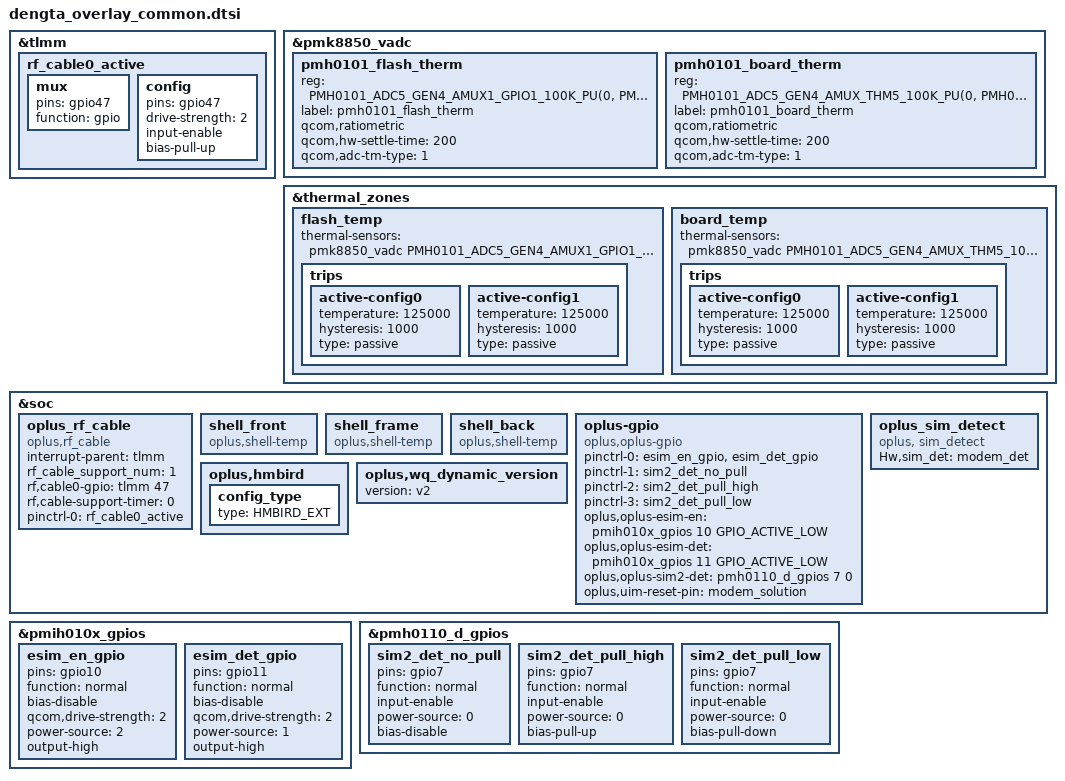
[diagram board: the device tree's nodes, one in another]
&tlmm {
    //#ifdef OPLUS_FEATURE_RF_CABLE_DETECT
    rf_cable0_active: rf_cable0_active {
        mux {
            pins = "gpio47";
            function = "gpio";
        };
        config {
            pins = "gpio47";
            drive-strength = <2>;
            input-enable;
            bias-pull-up;
        };
    };
    //#endif /* OPLUS_FEATURE_RF_CABLE_DETECT */
};

&pmk8850_vadc {
    pmh0101_flash_therm {
        reg = <PMH0101_ADC5_GEN4_AMUX1_GPIO1_100K_PU(0, PMH0101_SID)>;
        label = "pmh0101_flash_therm";
        qcom,ratiometric;
        qcom,hw-settle-time = <200>;
        qcom,adc-tm-type = <1>;
    };
    pmh0101_board_therm {
        reg = <PMH0101_ADC5_GEN4_AMUX_THM5_100K_PU(0, PMH0101_SID)>;
        label = "pmh0101_board_therm";
        qcom,ratiometric;
        qcom,hw-settle-time = <200>;
        qcom,adc-tm-type = <1>;
    };
};

&thermal_zones {
    flash_temp {
        thermal-sensors = <&pmk8850_vadc
            PMH0101_ADC5_GEN4_AMUX1_GPIO1_100K_PU(0, PMH0101_SID)>;

        trips {
            active-config0 {
                temperature = <125000>;
                hysteresis = <1000>;
                type = "passive";
            };

            active-config1 {
                temperature = <125000>;
                hysteresis = <1000>;
                type = "passive";
            };
        };
    };
    board_temp {
        thermal-sensors = <&pmk8850_vadc
            PMH0101_ADC5_GEN4_AMUX_THM5_100K_PU(0, PMH0101_SID)>;

        trips {
            active-config0 {
                temperature = <125000>;
                hysteresis = <1000>;
                type = "passive";
            };

            active-config1 {
                temperature = <125000>;
                hysteresis = <1000>;
                type = "passive";
            };
        };
    };
};

&soc {
    //#ifdef OPLUS_FEATURE_RF_CABLE_DETECT
    oplus_rf_cable {
        compatible = "oplus,rf_cable";
        interrupt-parent = <&tlmm>;
        rf_cable_support_num = <1>;
        rf,cable0-gpio = <&tlmm 47 0>;
        rf,cable-support-timer = <0>;
        pinctrl-names = "rf_cable_active";
        pinctrl-0 = <&rf_cable0_active>;
    };
    //#endif /* OPLUS_FEATURE_RF_CABLE_DETECT */

    //#ifdef OPLUS_FEATURE_THERMAL_HORAE
    shell_front {
        compatible = "oplus,shell-temp";
    };

    shell_frame {
        compatible = "oplus,shell-temp";
    };

    shell_back {
        compatible = "oplus,shell-temp";
    };
    //#endif /* OPLUS_FEATURE_THERMAL_HORAE */

  //#ifdef OPLUS_FEATURE_ESIM
  oplus-gpio {
    compatible = "oplus,oplus-gpio";
    pinctrl-names = "oplus_esim", "sim2_det_no_pull", "sim2_det_pull_high", "sim2_det_pull_low";
    pinctrl-0 = <&esim_en_gpio &esim_det_gpio>;
    pinctrl-1 = <&sim2_det_no_pull>;
    pinctrl-2 = <&sim2_det_pull_high>;
    pinctrl-3 = <&sim2_det_pull_low>;
    oplus,oplus-esim-en = <&pmih010x_gpios 10 GPIO_ACTIVE_LOW>;
    oplus,oplus-esim-det = <&pmih010x_gpios 11 GPIO_ACTIVE_LOW>;
    oplus,oplus-sim2-det = <&pmh0110_d_gpios 7 0>;
    oplus,uim-reset-pin = "modem_solution";
  };
  oplus_sim_detect {
    compatible = "oplus, sim_detect";
    Hw,sim_det = "modem_det";
  };
  //#endif /*OPLUS_FEATURE_ESIM*/
  //#ifdef CONFIG_HMBIRD_SCHED
  oplus,hmbird {
    config_type {
      type = "HMBIRD_EXT";
    };
  };
  //#endif /* CONFIG_HMBIRD_SCHED */

  //#ifdef CONFIG_OPLUS_WQ_DYNAMIC_PRIORITY
  oplus,wq_dynamic_version {
      version = "v2";
  };
  //#endif /* CONFIG_OPLUS_WQ_DYNAMIC_PRIORITY */
};

&pmih010x_gpios {
  esim_en_gpio: esim_en_gpio {
      pins = "gpio10";
      function = "normal";
      bias-disable; /* NO pull */
      qcom,drive-strength = <2>; /* 2 MA */
      power-source = <2>; /* 1.2V */
      output-high;
  };
esim_det_gpio: esim_det_gpio {
      pins = "gpio11";
      function = "normal";
      bias-disable; /* NO pull */
      qcom,drive-strength = <2>; /* 2 MA */
      power-source = <1>; /* 1.8V */
      output-high;
  };
};

&pmh0110_d_gpios {
    sim2_det_no_pull: sim2_det_no_pull {
        pins = "gpio7";
        function = "normal";
        input-enable;
        power-source = <0>;
        bias-disable;
    };

    sim2_det_pull_high: sim2_det_pull_high {
        pins = "gpio7";
        function = "normal";
        input-enable;
        power-source = <0>;
        bias-pull-up;
    };

    sim2_det_pull_low: sim2_det_pull_low {
        pins = "gpio7";
        function = "normal";
        input-enable;
        power-source = <0>;
        bias-pull-down;
    };
};
